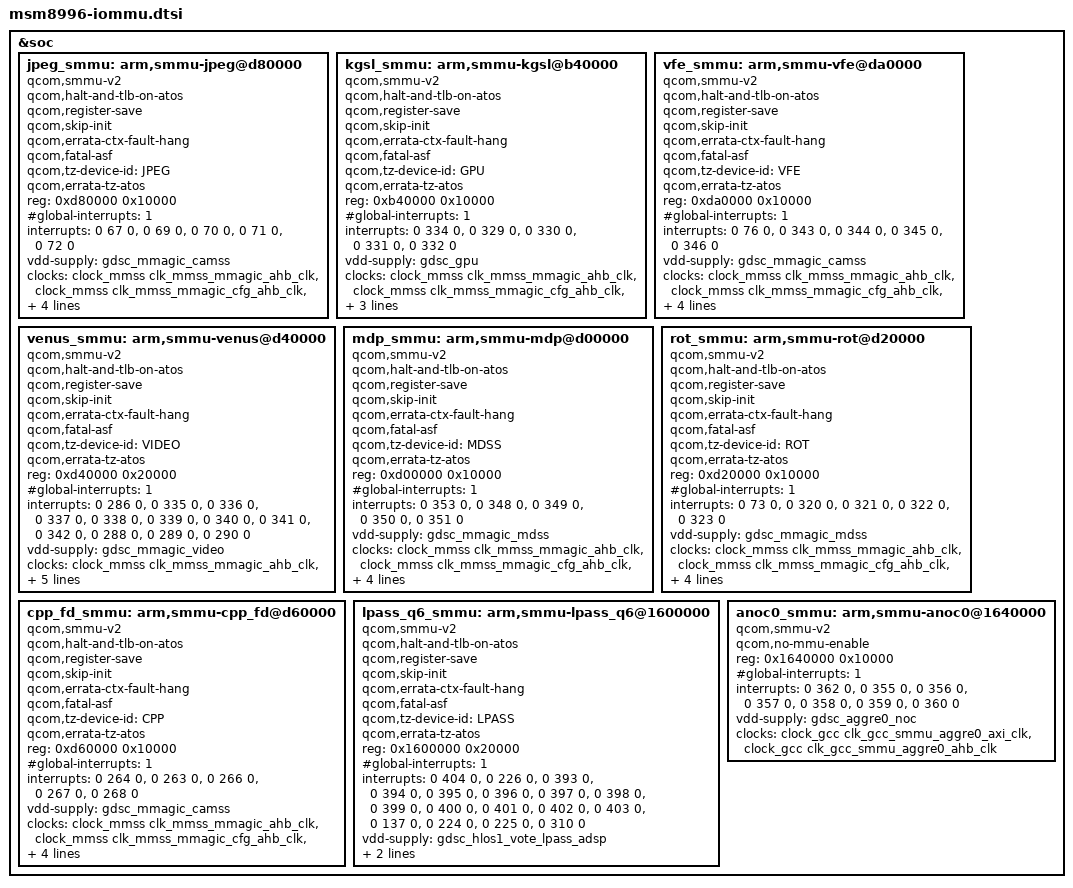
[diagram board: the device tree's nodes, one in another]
/* Copyright (c) 2014-2015, The Linux Foundation. All rights reserved.
 *
 * This program is free software; you can redistribute it and/or modify
 * it under the terms of the GNU General Public License version 2 and
 * only version 2 as published by the Free Software Foundation.
 *
 * This program is distributed in the hope that it will be useful,
 * but WITHOUT ANY WARRANTY; without even the implied warranty of
 * MERCHANTABILITY or FITNESS FOR A PARTICULAR PURPOSE.  See the
 * GNU General Public License for more details.
 */

#include <dt-bindings/clock/msm-clocks-8996.h>

&soc {
	jpeg_smmu: arm,smmu-jpeg@d80000 {
		compatible = "qcom,smmu-v2";
		qcom,halt-and-tlb-on-atos;
		qcom,register-save;
		qcom,skip-init;
		qcom,errata-ctx-fault-hang;
		qcom,fatal-asf;
		qcom,tz-device-id = "JPEG";
		qcom,errata-tz-atos;
		reg = <0xd80000 0x10000>;
		#global-interrupts = <1>;

		interrupts = <0 67 0>, <0 69 0>, <0 70 0>, <0 71 0>, <0 72 0>;

		#iommu-cells = <1>;
		vdd-supply = <&gdsc_mmagic_camss>;
		clocks = <&clock_mmss clk_mmss_mmagic_ahb_clk>,
			<&clock_mmss clk_mmss_mmagic_cfg_ahb_clk>,
			<&clock_mmss clk_smmu_jpeg_ahb_clk>,
			<&clock_mmss clk_smmu_jpeg_axi_clk>,
			<&clock_mmss clk_mmagic_bimc_axi_clk>,
			<&clock_mmss clk_mmagic_camss_axi_clk>;
		clock-names = "mmagic_ahb_clk", "mmagic_cfg_ahb_clk",
			"jpeg_ahb_clk", "jpeg_axi_clk",
			"mmagic_bimc_axi_clk", "mmagic_camss_axi_clk";
		#clock-cells = <1>;
	};

	kgsl_smmu: arm,smmu-kgsl@b40000 {
		compatible = "qcom,smmu-v2";
		qcom,halt-and-tlb-on-atos;
		qcom,register-save;
		qcom,skip-init;
		qcom,errata-ctx-fault-hang;
		qcom,fatal-asf;
		qcom,tz-device-id = "GPU";
		qcom,errata-tz-atos;
		reg = <0xb40000 0x10000>;
		#global-interrupts = <1>;

		interrupts = <0 334 0>, <0 329 0>, <0 330 0>,
			<0 331 0>, <0 332 0>;

		#iommu-cells = <1>;
		vdd-supply = <&gdsc_gpu>;
		clocks = <&clock_mmss clk_mmss_mmagic_ahb_clk>,
			<&clock_mmss clk_mmss_mmagic_cfg_ahb_clk>,
			<&clock_gpu clk_gpu_ahb_clk>,
			<&clock_gcc clk_gcc_mmss_bimc_gfx_clk>,
			<&clock_gcc clk_gcc_bimc_gfx_clk>;
		clock-names = "mmagic_ahb_clk", "mmagic_cfg_ahb_clk", "gpu_ahb_clk",
			"gcc_mmss_bimc_gfx_clk", "gcc_bimc_gfx_clk";
		#clock-cells = <1>;
	};

	vfe_smmu: arm,smmu-vfe@da0000 {
		compatible = "qcom,smmu-v2";
		qcom,halt-and-tlb-on-atos;
		qcom,register-save;
		qcom,skip-init;
		qcom,errata-ctx-fault-hang;
		qcom,fatal-asf;
		qcom,tz-device-id = "VFE";
		qcom,errata-tz-atos;
		reg = <0xda0000 0x10000>;
		#global-interrupts = <1>;

		interrupts = <0 76 0>, <0 343 0>, <0 344 0>, <0 345 0>,
			   <0 346 0>;

		#iommu-cells = <1>;
		vdd-supply = <&gdsc_mmagic_camss>;
		clocks = <&clock_mmss clk_mmss_mmagic_ahb_clk>,
			<&clock_mmss clk_mmss_mmagic_cfg_ahb_clk>,
			<&clock_mmss clk_smmu_vfe_ahb_clk>,
			<&clock_mmss clk_smmu_vfe_axi_clk>,
			<&clock_mmss clk_mmagic_bimc_axi_clk>,
			<&clock_mmss clk_mmagic_camss_axi_clk>;
		clock-names = "mmagic_ahb_clk", "mmagic_cfg_ahb_clk",
			"vfe_ahb_clk", "vfe_axi_clk",
			"mmagic_bimc_axi_clk", "mmagic_camss_axi_clk";
		#clock-cells = <1>;
	};

	venus_smmu: arm,smmu-venus@d40000 {
		compatible = "qcom,smmu-v2";
		qcom,halt-and-tlb-on-atos;
		qcom,register-save;
		qcom,skip-init;
		qcom,errata-ctx-fault-hang;
		qcom,fatal-asf;
		qcom,tz-device-id = "VIDEO";
		qcom,errata-tz-atos;
		reg = <0xd40000 0x20000>;
		#global-interrupts = <1>;

		interrupts = <0 286 0>, <0 335 0>, <0 336 0>, <0 337 0>,
		<0 338 0>, <0 339 0>, <0 340 0>, <0 341 0>, <0 342 0>,
		<0 288 0>, <0 289 0>, <0 290 0>;

		#iommu-cells = <1>;
		vdd-supply = <&gdsc_mmagic_video>;
		clocks = <&clock_mmss clk_mmss_mmagic_ahb_clk>,
			<&clock_mmss clk_mmss_mmagic_cfg_ahb_clk>,
			<&clock_mmss clk_smmu_video_ahb_clk>,
			<&clock_mmss clk_smmu_video_axi_clk>,
			<&clock_mmss clk_mmagic_bimc_axi_clk>,
			<&clock_mmss clk_mmagic_video_axi_clk>;
		clock-names = "mmagic_ahb_clk", "mmagic_cfg_ahb_clk",
			"video_ahb_clk", "video_axi_clk",
			"mmagic_bimc_axi_clk", "mmagic_video_axi_clk";
		#clock-cells = <1>;
	};

	mdp_smmu: arm,smmu-mdp@d00000 {
		compatible = "qcom,smmu-v2";
		qcom,halt-and-tlb-on-atos;
		qcom,register-save;
		qcom,skip-init;
		qcom,errata-ctx-fault-hang;
		qcom,fatal-asf;
		qcom,tz-device-id = "MDSS";
		qcom,errata-tz-atos;
		reg = <0xd00000 0x10000>;
		#global-interrupts = <1>;

		interrupts = <0 353 0>, <0 348 0>, <0 349 0>, <0 350 0>,
			   <0 351 0>;

		#iommu-cells = <1>;
		vdd-supply = <&gdsc_mmagic_mdss>;
		clocks = <&clock_mmss clk_mmss_mmagic_ahb_clk>,
			<&clock_mmss clk_mmss_mmagic_cfg_ahb_clk>,
			<&clock_mmss clk_smmu_mdp_ahb_clk>,
			<&clock_mmss clk_smmu_mdp_axi_clk>,
			<&clock_mmss clk_mmagic_bimc_axi_clk>,
			<&clock_mmss clk_mmagic_mdss_axi_clk>;
		clock-names = "mmagic_ahb_clk", "mmagic_cfg_ahb_clk",
			"mdp_ahb_clk", "mdp_axi_clk",
			"mmagic_bimc_axi_clk", "mmagic_mdss_axi_clk";
		#clock-cells = <1>;
	};

	rot_smmu: arm,smmu-rot@d20000 {
		compatible = "qcom,smmu-v2";
		qcom,halt-and-tlb-on-atos;
		qcom,register-save;
		qcom,skip-init;
		qcom,errata-ctx-fault-hang;
		qcom,fatal-asf;
		qcom,tz-device-id = "ROT";
		qcom,errata-tz-atos;
		reg = <0xd20000 0x10000>;
		#global-interrupts = <1>;

		interrupts = <0 73 0>, <0 320 0>, <0 321 0>, <0 322 0>, <0 323 0>;

		#iommu-cells = <1>;
		vdd-supply = <&gdsc_mmagic_mdss>;
		clocks = <&clock_mmss clk_mmss_mmagic_ahb_clk>,
			<&clock_mmss clk_mmss_mmagic_cfg_ahb_clk>,
			<&clock_mmss clk_smmu_rot_ahb_clk>,
			<&clock_mmss clk_smmu_rot_axi_clk>,
			<&clock_mmss clk_mmagic_bimc_axi_clk>,
			<&clock_mmss clk_mmagic_mdss_axi_clk>;
		clock-names = "mmagic_ahb_clk", "mmagic_cfg_ahb_clk",
			"rot_ahb_clk", "rot_axi_clk",
			"mmagic_bimc_axi_clk", "mmagic_mdss_axi_clk";
		#clock-cells = <1>;
	};

	cpp_fd_smmu: arm,smmu-cpp_fd@d60000 {
		compatible = "qcom,smmu-v2";
		qcom,halt-and-tlb-on-atos;
		qcom,register-save;
		qcom,skip-init;
		qcom,errata-ctx-fault-hang;
		qcom,fatal-asf;
		qcom,tz-device-id = "CPP";
		qcom,errata-tz-atos;
		reg = <0xd60000 0x10000>;
		#global-interrupts = <1>;

		interrupts = <0 264 0>, <0 263 0>, <0 266 0>, <0 267 0>,
			   <0 268 0>;

		#iommu-cells = <1>;
		vdd-supply = <&gdsc_mmagic_camss>;
		clocks = <&clock_mmss clk_mmss_mmagic_ahb_clk>,
			<&clock_mmss clk_mmss_mmagic_cfg_ahb_clk>,
			<&clock_mmss clk_smmu_cpp_ahb_clk>,
			<&clock_mmss clk_smmu_cpp_axi_clk>,
			<&clock_mmss clk_mmagic_bimc_axi_clk>,
			<&clock_mmss clk_mmagic_camss_axi_clk>;
		clock-names = "mmagic_ahb_clk", "mmagic_cfg_ahb_clk",
			"cpp_ahb_clk", "cpp_axi_clk",
			"mmagic_bimc_axi_clk", "mmagic_camss_axi_clk";
		#clock-cells = <1>;
	};

	lpass_q6_smmu: arm,smmu-lpass_q6@1600000 {
		compatible = "qcom,smmu-v2";
		qcom,halt-and-tlb-on-atos;
		qcom,register-save;
		qcom,skip-init;
		qcom,errata-ctx-fault-hang;
		qcom,fatal-asf;
		qcom,tz-device-id = "LPASS";
		qcom,errata-tz-atos;
		reg = <0x1600000 0x20000>;
		#global-interrupts = <1>;

		interrupts = <0 404 0>, <0 226 0>, <0 393 0>, <0 394 0>,
			   <0 395 0>, <0 396 0>, <0 397 0>, <0 398 0>,
			   <0 399 0>, <0 400 0>, <0 401 0>, <0 402 0>,
			   <0 403 0>, <0 137 0>, <0 224 0>, <0 225 0>,
			   <0 310 0>;

		#iommu-cells = <1>;
		vdd-supply = <&gdsc_hlos1_vote_lpass_adsp>;
		clocks = <&clock_gcc clk_hlos1_vote_lpass_adsp_smmu_clk>;
		clock-names = "lpass_q6_smmu_clocks";
		#clock-cells = <1>;
	};

	anoc0_smmu: arm,smmu-anoc0@1640000 {
		compatible = "qcom,smmu-v2";
		qcom,no-mmu-enable;
		reg = <0x1640000 0x10000>;
		#global-interrupts = <1>;

		interrupts = <0 362 0>, <0 355 0>, <0 356 0>, <0 357 0>,
			   <0 358 0>, <0 359 0>, <0 360 0>;

		#iommu-cells = <1>;
		vdd-supply = <&gdsc_aggre0_noc>;
		clocks = <&clock_gcc clk_gcc_smmu_aggre0_axi_clk>,
			<&clock_gcc clk_gcc_smmu_aggre0_ahb_clk>;
		clock-names = "smmu_aggre0_axi_clk", "smmu_aggre0_ahb_clk";
		#clock-cells = <1>;
	};
};

#include "msm8996-iommu-impl-defs.dtsi"
